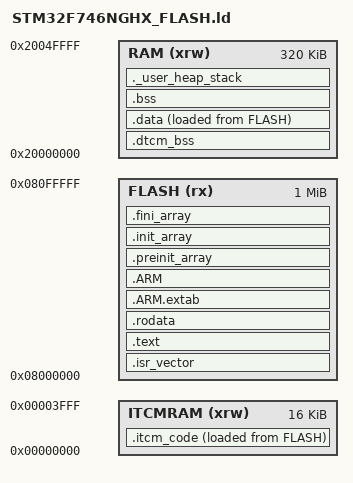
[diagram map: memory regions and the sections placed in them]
/*
******************************************************************************
**
** @file        : LinkerScript.ld
**
** @author      : Auto-generated by STM32CubeIDE
**
**  Abstract    : Linker script for STM32F746G-DISCO Board embedding STM32F746NGHx Device from stm32f7 series
**                      1024Kbytes FLASH
**                      320Kbytes RAM
**
**                Set heap size, stack size and stack location according
**                to application requirements.
**
**                Set memory bank area and size if external memory is used
**
**  Target      : STMicroelectronics STM32
**
**  Distribution: The file is distributed as is, without any warranty
**                of any kind.
**
******************************************************************************
** @attention
**
** Copyright (c) 2023 STMicroelectronics.
** All rights reserved.
**
** This software is licensed under terms that can be found in the LICENSE file
** in the root directory of this software component.
** If no LICENSE file comes with this software, it is provided AS-IS.
**
******************************************************************************
*/

/* Entry Point */
ENTRY(Reset_Handler)

/* Highest address of the user mode stack */
_estack = ORIGIN(RAM) + LENGTH(RAM); /* end of "RAM" Ram type memory */

_Min_Heap_Size = 0x200; /* required amount of heap */
_Min_Stack_Size = 0x400; /* required amount of stack */

/* Memories definition.
   RAM 320K = DTCM 64K (0x20000000~0x2000FFFF, 코어 직결) + SRAM1 240K + SRAM2 16K.
   물리적으로 다른 메모리지만 주소가 연속이라 하나의 영역으로 두고,
   DTCM에 두고 싶은 것만 .dtcm_bss 섹션(영역 선두 = DTCM)으로 앞세운다.
   ITCMRAM 16K는 핫 커널 코드 전용 (실측 0.50 cyc/insn, 플래시 대비 최대 2.5배). */
MEMORY
{
  ITCMRAM  (xrw)   : ORIGIN = 0x00000000,   LENGTH = 16K
  RAM    (xrw)    : ORIGIN = 0x20000000,   LENGTH = 320K
  FLASH    (rx)    : ORIGIN = 0x8000000,   LENGTH = 1024K
}

/* Sections */
SECTIONS
{
  /* The startup code into "FLASH" Rom type memory */
  .isr_vector :
  {
    . = ALIGN(4);
    KEEP(*(.isr_vector)) /* Startup code */
    . = ALIGN(4);
  } >FLASH

  /* The program code and other data into "FLASH" Rom type memory */
  .text :
  {
    . = ALIGN(4);
    *(.text)           /* .text sections (code) */
    *(.text*)          /* .text* sections (code) */
    *(.glue_7)         /* glue arm to thumb code */
    *(.glue_7t)        /* glue thumb to arm code */
    *(.eh_frame)

    KEEP (*(.init))
    KEEP (*(.fini))

    . = ALIGN(4);
    _etext = .;        /* define a global symbols at end of code */
  } >FLASH

  /* Constant data into "FLASH" Rom type memory */
  .rodata :
  {
    . = ALIGN(4);
    *(.rodata)         /* .rodata sections (constants, strings, etc.) */
    *(.rodata*)        /* .rodata* sections (constants, strings, etc.) */
    . = ALIGN(4);
  } >FLASH

  .ARM.extab   : {
    . = ALIGN(4);
    *(.ARM.extab* .gnu.linkonce.armextab.*)
    . = ALIGN(4);
  } >FLASH

  .ARM : {
    . = ALIGN(4);
    __exidx_start = .;
    *(.ARM.exidx*)
    __exidx_end = .;
    . = ALIGN(4);
  } >FLASH

  .preinit_array     :
  {
    . = ALIGN(4);
    PROVIDE_HIDDEN (__preinit_array_start = .);
    KEEP (*(.preinit_array*))
    PROVIDE_HIDDEN (__preinit_array_end = .);
    . = ALIGN(4);
  } >FLASH

  .init_array :
  {
    . = ALIGN(4);
    PROVIDE_HIDDEN (__init_array_start = .);
    KEEP (*(SORT(.init_array.*)))
    KEEP (*(.init_array*))
    PROVIDE_HIDDEN (__init_array_end = .);
    . = ALIGN(4);
  } >FLASH

  .fini_array :
  {
    . = ALIGN(4);
    PROVIDE_HIDDEN (__fini_array_start = .);
    KEEP (*(SORT(.fini_array.*)))
    KEEP (*(.fini_array*))
    PROVIDE_HIDDEN (__fini_array_end = .);
    . = ALIGN(4);
  } >FLASH

  /* SNN 핫 커널 코드: 플래시에 적재(LMA)되고 부팅 시 snn_itcm_init()이
     ITCM RAM(VMA 0x00000000)으로 복사한다. SNN_OPT_ITCM이 꺼진 빌드에서는
     비어 있어 레이아웃이 기존과 동일하다. 아웃오브레인지 호출의 베니어도
     섹션 안에 함께 배치되므로 복사 범위에 포함된다. */
  _sitcm_code_load = LOADADDR(.itcm_code);
  .itcm_code :
  {
    . = ALIGN(4);
    _sitcm_code = .;
    *(.itcm_code)
    *(.itcm_code*)
    . = ALIGN(4);
    _eitcm_code = .;
  } >ITCMRAM AT> FLASH

  /* Used by the startup to initialize data */
  _sidata = LOADADDR(.data);

  /* SNN 핫 데이터 (가중치 사본·im2col·LIF 상태): RAM 영역 선두 = DTCM 64K.
     런타임에 코드가 채우므로 적재/제로화가 필요 없다(NOLOAD).
     SNN_OPT_DTCM이 꺼진 빌드에서는 비어 있어 .data가 기존처럼 0x20000000에 온다. */
  .dtcm_bss (NOLOAD) :
  {
    . = ALIGN(4);
    _sdtcm_bss = .;
    *(.dtcm_bss)
    *(.dtcm_bss*)
    . = ALIGN(4);
    _edtcm_bss = .;
  } >RAM
  ASSERT(_edtcm_bss <= 0x20010000, ".dtcm_bss가 DTCM 64KB를 넘었다")

  /* Initialized data sections into "RAM" Ram type memory */
  .data :
  {
    . = ALIGN(4);
    _sdata = .;        /* create a global symbol at data start */
    *(.data)           /* .data sections */
    *(.data*)          /* .data* sections */
    *(.RamFunc)        /* .RamFunc sections */
    *(.RamFunc*)       /* .RamFunc* sections */

    . = ALIGN(4);
    _edata = .;        /* define a global symbol at data end */

  } >RAM AT> FLASH

  /* Uninitialized data section into "RAM" Ram type memory */
  . = ALIGN(4);
  .bss :
  {
    /* This is used by the startup in order to initialize the .bss section */
    _sbss = .;         /* define a global symbol at bss start */
    __bss_start__ = _sbss;
    *(.bss)
    *(.bss*)
    *(COMMON)

    . = ALIGN(4);
    _ebss = .;         /* define a global symbol at bss end */
    __bss_end__ = _ebss;
  } >RAM

  /* User_heap_stack section, used to check that there is enough "RAM" Ram  type memory left */
  ._user_heap_stack :
  {
    . = ALIGN(8);
    PROVIDE ( end = . );
    PROVIDE ( _end = . );
    . = . + _Min_Heap_Size;
    . = . + _Min_Stack_Size;
    . = ALIGN(8);
  } >RAM

  /* Remove information from the compiler libraries */
  /DISCARD/ :
  {
    libc.a ( * )
    libm.a ( * )
    libgcc.a ( * )
  }

  .ARM.attributes 0 : { *(.ARM.attributes) }
}
